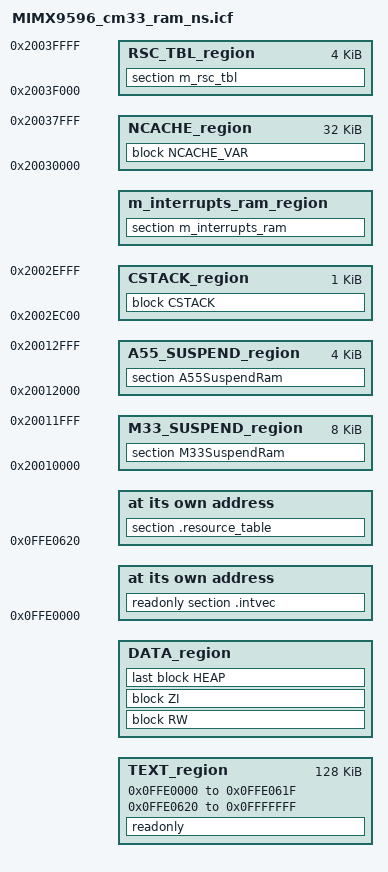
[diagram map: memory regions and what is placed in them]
/*
** ###################################################################
**     Processors:          MIMX9596CVTxLAA_cm33
**                          MIMX9596DVTxMAA_cm33
**                          MIMX9596XVTxKAA_cm33
**
**     Compiler:            IAR ANSI C/C++ Compiler for ARM
**     Reference manual:    iMX95RM rev1 draftM
**     Version:             rev. 1.0, 2021-11-16
**     Build:               b230322
**
**     Abstract:
**         Linker file for the IAR ANSI C/C++ Compiler for ARM
**
**     Copyright 2016 Freescale Semiconductor, Inc.
**     Copyright 2016-2023 NXP
**     All rights reserved.
**
**     SPDX-License-Identifier: BSD-3-Clause
**
**     http:                 www.nxp.com
**     mail:                 support@nxp.com
**
** ###################################################################
*/


define symbol __ram_vector_table_size__ =  isdefinedsymbol(__ram_vector_table__) ? 0x00000620 : 0;
define symbol __ram_vector_table_offset__ =  isdefinedsymbol(__ram_vector_table__) ? 0x0000061F : 0;

define symbol m_interrupts_start       = 0x0FFE0000;
define symbol m_interrupts_end         = 0x0FFE061F;

define symbol m_text_start             = 0x0FFE0620;
define symbol m_text_end               = 0x0FFFFFFF;

define symbol m_m33_suspend_ram_start  = 0x20010000;
define symbol m_m33_suspend_ram_end    = 0x20011FFF;

define symbol m_a55_suspend_ram_start  = 0x20012000;
define symbol m_a55_suspend_ram_end    = 0x20012FFF;

define symbol m_interrupts_ram_start   = 0x20023000;
define symbol m_interrupts_ram_end     = 0x20023000 + __ram_vector_table_offset__;

define symbol m_data_start             = m_interrupts_ram_start + __ram_vector_table_size__;
define symbol m_data_end               = 0x2002EFFF;

define symbol m_ncache_start           = 0x20030000;
define symbol m_ncache_end             = 0x20037FFF;

define symbol m_rsc_tbl_start          = 0x2003F000;
define symbol m_rsc_tbl_end            = 0x2003FFFF;

define exported symbol __NCACHE_REGION_START   = m_ncache_start;
define exported symbol __NCACHE_REGION_SIZE    = m_ncache_end - m_ncache_start + 1;
/* Sizes */
if (isdefinedsymbol(__stack_size__)) {
  define symbol __size_cstack__        = __stack_size__;
} else {
  define symbol __size_cstack__        = 0x0400;
}

if (isdefinedsymbol(__heap_size__)) {
  define symbol __size_heap__          = __heap_size__;
} else {
  define symbol __size_heap__          = 0x0400;
}

define exported symbol __VECTOR_TABLE  = m_interrupts_start;
define exported symbol __VECTOR_RAM    = isdefinedsymbol(__ram_vector_table__) ? m_interrupts_ram_start : m_interrupts_start;
define exported symbol __RAM_VECTOR_TABLE_SIZE = __ram_vector_table_size__;

define memory mem with size = 4G;
define region TEXT_region = mem:[from m_interrupts_start to m_interrupts_end]
                          | mem:[from m_text_start to m_text_end];
define region DATA_region = mem:[from m_data_start to m_data_end-__size_cstack__];
define region RSC_TBL_region = mem:[from m_rsc_tbl_start to m_rsc_tbl_end];
define region CSTACK_region = mem:[from m_data_end-__size_cstack__+1 to m_data_end];
define region m_interrupts_ram_region = mem:[from m_interrupts_ram_start to m_interrupts_ram_end];
define region M33_SUSPEND_region = mem:[from m_m33_suspend_ram_start to m_m33_suspend_ram_end];
define region A55_SUSPEND_region = mem:[from m_a55_suspend_ram_start to m_a55_suspend_ram_end];
define region NCACHE_region = mem:[from m_ncache_start to m_ncache_end];

define block CSTACK    with alignment = 8, size = __size_cstack__   { };
define block HEAP      with alignment = 8, size = __size_heap__     { };
define block RW        { readwrite };
define block ZI        { zi };
define block NCACHE_VAR    { section NonCacheable , section NonCacheable.init };

initialize by copy { readwrite, section .textrw };
do not initialize  { section .noinit, section M33SuspendRam, section A55SuspendRam };

keep{section .resource_table};

place at address mem: m_interrupts_start    { readonly section .intvec };
".resource_table": place at address mem: m_text_start {section .resource_table};
place in TEXT_region                        { readonly };
place in DATA_region                        { block RW };
place in DATA_region                        { block ZI };
place in DATA_region                        { last block HEAP };
place in CSTACK_region                      { block CSTACK };
place in RSC_TBL_region                     { section m_rsc_tbl };
place in m_interrupts_ram_region            { section m_interrupts_ram };
place in M33_SUSPEND_region                 { section M33SuspendRam };
place in A55_SUSPEND_region                 { section A55SuspendRam };
place in NCACHE_region                      { block NCACHE_VAR };
